AUTOSAR XML (schema 4-2-2)
package /ComponentTypes
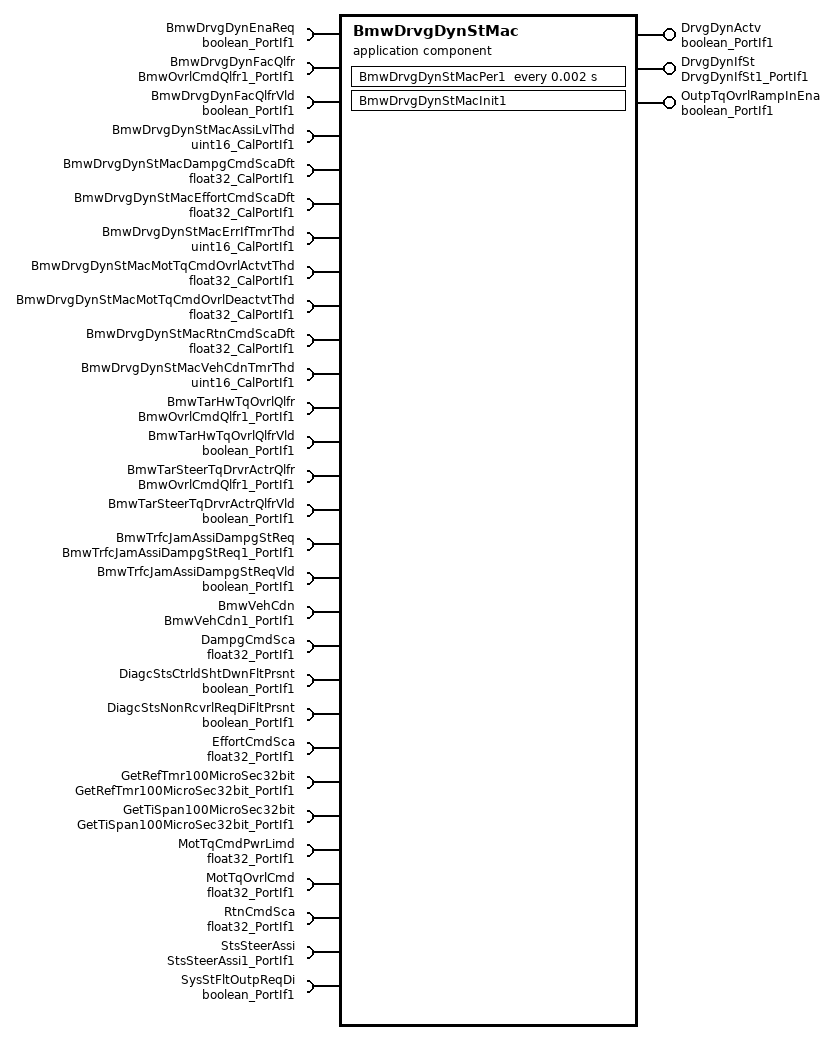
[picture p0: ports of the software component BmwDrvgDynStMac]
  application sw component type BmwDrvgDynStMac
    provide port DrvgDynActv: nonqueued-sender-com-spec{data-element=Logl, init-value=0}, provided-interface=boolean_PortIf1
    provide port DrvgDynIfSt: nonqueued-sender-com-spec{data-element=Val, init-value=128}, provided-interface=DrvgDynIfSt1_PortIf1
    provide port OutpTqOvrlRampInEna: nonqueued-sender-com-spec{data-element=Logl, init-value=0}, provided-interface=boolean_PortIf1
    29 x require port:
      BmwDrvgDynEnaReq: nonqueued-receiver-com-spec{data-element=Logl, filter=data-filter-type=ALWAYS, init-value=0}, required-interface=boolean_PortIf1
      BmwDrvgDynFacQlfr: nonqueued-receiver-com-spec{data-element=Val, filter=data-filter-type=ALWAYS, init-value=15}, required-interface=BmwOvrlCmdQlfr1_PortIf1
      BmwDrvgDynFacQlfrVld: nonqueued-receiver-com-spec{data-element=Logl, filter=data-filter-type=ALWAYS, init-value=0}, required-interface=boolean_PortIf1
      BmwDrvgDynStMacAssiLvlThd: parameter-require-com-spec{init-value=20, parameter=Val}, required-interface=uint16_CalPortIf1
      BmwDrvgDynStMacDampgCmdScaDft: parameter-require-com-spec{init-value=1, parameter=Val}, required-interface=float32_CalPortIf1
      BmwDrvgDynStMacEffortCmdScaDft: parameter-require-com-spec{init-value=1, parameter=Val}, required-interface=float32_CalPortIf1
      BmwDrvgDynStMacErrIfTmrThd: parameter-require-com-spec{init-value=20, parameter=Val}, required-interface=uint16_CalPortIf1
      BmwDrvgDynStMacMotTqCmdOvrlActvtThd: parameter-require-com-spec{init-value=0, parameter=Val}, required-interface=float32_CalPortIf1
      BmwDrvgDynStMacMotTqCmdOvrlDeactvtThd: parameter-require-com-spec{init-value=0, parameter=Val}, required-interface=float32_CalPortIf1
      BmwDrvgDynStMacRtnCmdScaDft: parameter-require-com-spec{init-value=1, parameter=Val}, required-interface=float32_CalPortIf1
      BmwDrvgDynStMacVehCdnTmrThd: parameter-require-com-spec{init-value=20, parameter=Val}, required-interface=uint16_CalPortIf1
      BmwTarHwTqOvrlQlfr: nonqueued-receiver-com-spec{data-element=Val, filter=data-filter-type=ALWAYS, init-value=15}, required-interface=BmwOvrlCmdQlfr1_PortIf1
      BmwTarHwTqOvrlQlfrVld: nonqueued-receiver-com-spec{data-element=Logl, filter=data-filter-type=ALWAYS, init-value=0}, required-interface=boolean_PortIf1
      BmwTarSteerTqDrvrActrQlfr: nonqueued-receiver-com-spec{data-element=Val, filter=data-filter-type=ALWAYS, init-value=15}, required-interface=BmwOvrlCmdQlfr1_PortIf1
      BmwTarSteerTqDrvrActrQlfrVld: nonqueued-receiver-com-spec{data-element=Logl, filter=data-filter-type=ALWAYS, init-value=0}, required-interface=boolean_PortIf1
      BmwTrfcJamAssiDampgStReq: nonqueued-receiver-com-spec{data-element=Val, filter=data-filter-type=ALWAYS, init-value=1}, required-interface=BmwTrfcJamAssiDampgStReq1_PortIf1
      BmwTrfcJamAssiDampgStReqVld: nonqueued-receiver-com-spec{data-element=Logl, filter=data-filter-type=ALWAYS, init-value=0}, required-interface=boolean_PortIf1
      BmwVehCdn: nonqueued-receiver-com-spec{data-element=Val, filter=data-filter-type=ALWAYS, init-value=15}, required-interface=BmwVehCdn1_PortIf1
      DampgCmdSca: nonqueued-receiver-com-spec{data-element=Val, filter=data-filter-type=ALWAYS, init-value=1}, required-interface=float32_PortIf1
      DiagcStsCtrldShtDwnFltPrsnt: nonqueued-receiver-com-spec{data-element=Logl, filter=data-filter-type=ALWAYS, init-value=0}, required-interface=boolean_PortIf1
      DiagcStsNonRcvrlReqDiFltPrsnt: nonqueued-receiver-com-spec{data-element=Logl, filter=data-filter-type=ALWAYS, init-value=0}, required-interface=boolean_PortIf1
      EffortCmdSca: nonqueued-receiver-com-spec{data-element=Val, filter=data-filter-type=ALWAYS, init-value=1}, required-interface=float32_PortIf1
      GetRefTmr100MicroSec32bit: client-com-spec=Oper, required-interface=GetRefTmr100MicroSec32bit_PortIf1
      GetTiSpan100MicroSec32bit: client-com-spec=Oper, required-interface=GetTiSpan100MicroSec32bit_PortIf1
      MotTqCmdPwrLimd: nonqueued-receiver-com-spec{data-element=Val, filter=data-filter-type=ALWAYS, init-value=0}, required-interface=float32_PortIf1
      MotTqOvrlCmd: nonqueued-receiver-com-spec{data-element=Val, filter=data-filter-type=ALWAYS, init-value=0}, required-interface=float32_PortIf1
      RtnCmdSca: nonqueued-receiver-com-spec{data-element=Val, filter=data-filter-type=ALWAYS, init-value=1}, required-interface=float32_PortIf1
      StsSteerAssi: nonqueued-receiver-com-spec{data-element=Val, filter=data-filter-type=ALWAYS, init-value=0}, required-interface=StsSteerAssi1_PortIf1
      SysStFltOutpReqDi: nonqueued-receiver-com-spec{data-element=Logl, filter=data-filter-type=ALWAYS, init-value=0}, required-interface=boolean_PortIf1
    behavior BmwDrvgDynStMac_InternalBehavior
      ar-typed-per-instance-memorys:
        7 x data, all with sw-calibration-access=READ-ONLY:
          AssiLvlActvtTi: type=uint32
          AssiLvlDeactvtTi: type=uint32
          ErrIfTi: type=uint32
          MotTqCmdPwrLimdCdnActvt: type=boolean
          MotTqCmdPwrLimdCdnDeactvt: type=boolean
          StMacSt: type=uint8
          VehCdnTi: type=uint32
      init event BmwDrvgDynStMac_InitEvent: start-on-event=BmwDrvgDynStMacInit1
      timing event TMT_BmwDrvgDynStMacPer1: start-on-event=BmwDrvgDynStMacPer1, period=0.002
      port-api-options:
        enable-take-address=false, error-handling=NO-TRANSFORMER-ERROR-HANDLING, indirect-api=false, port=BmwDrvgDynEnaReq
        enable-take-address=false, error-handling=NO-TRANSFORMER-ERROR-HANDLING, indirect-api=false, port=BmwDrvgDynFacQlfr
        enable-take-address=false, error-handling=NO-TRANSFORMER-ERROR-HANDLING, indirect-api=false, port=BmwDrvgDynFacQlfrVld
        enable-take-address=false, error-handling=NO-TRANSFORMER-ERROR-HANDLING, indirect-api=false, port=BmwDrvgDynStMacAssiLvlThd
        enable-take-address=false, error-handling=NO-TRANSFORMER-ERROR-HANDLING, indirect-api=false, port=BmwDrvgDynStMacDampgCmdScaDft
        enable-take-address=false, error-handling=NO-TRANSFORMER-ERROR-HANDLING, indirect-api=false, port=BmwDrvgDynStMacEffortCmdScaDft
        enable-take-address=false, error-handling=NO-TRANSFORMER-ERROR-HANDLING, indirect-api=false, port=BmwDrvgDynStMacErrIfTmrThd
        enable-take-address=false, error-handling=NO-TRANSFORMER-ERROR-HANDLING, indirect-api=false, port=BmwDrvgDynStMacMotTqCmdOvrlActvtThd
        enable-take-address=false, error-handling=NO-TRANSFORMER-ERROR-HANDLING, indirect-api=false, port=BmwDrvgDynStMacMotTqCmdOvrlDeactvtThd
        enable-take-address=false, error-handling=NO-TRANSFORMER-ERROR-HANDLING, indirect-api=false, port=BmwDrvgDynStMacRtnCmdScaDft
        enable-take-address=false, error-handling=NO-TRANSFORMER-ERROR-HANDLING, indirect-api=false, port=BmwDrvgDynStMacVehCdnTmrThd
        enable-take-address=false, error-handling=NO-TRANSFORMER-ERROR-HANDLING, indirect-api=false, port=BmwTarHwTqOvrlQlfr
        enable-take-address=false, error-handling=NO-TRANSFORMER-ERROR-HANDLING, indirect-api=false, port=BmwTarHwTqOvrlQlfrVld
        enable-take-address=false, error-handling=NO-TRANSFORMER-ERROR-HANDLING, indirect-api=false, port=BmwTarSteerTqDrvrActrQlfr
        enable-take-address=false, error-handling=NO-TRANSFORMER-ERROR-HANDLING, indirect-api=false, port=BmwTarSteerTqDrvrActrQlfrVld
        enable-take-address=false, error-handling=NO-TRANSFORMER-ERROR-HANDLING, indirect-api=false, port=BmwTrfcJamAssiDampgStReq
        enable-take-address=false, error-handling=NO-TRANSFORMER-ERROR-HANDLING, indirect-api=false, port=BmwTrfcJamAssiDampgStReqVld
        enable-take-address=false, error-handling=NO-TRANSFORMER-ERROR-HANDLING, indirect-api=false, port=BmwVehCdn
        enable-take-address=false, error-handling=NO-TRANSFORMER-ERROR-HANDLING, indirect-api=false, port=DampgCmdSca
        enable-take-address=false, error-handling=NO-TRANSFORMER-ERROR-HANDLING, indirect-api=false, port=DiagcStsCtrldShtDwnFltPrsnt
        enable-take-address=false, error-handling=NO-TRANSFORMER-ERROR-HANDLING, indirect-api=false, port=DiagcStsNonRcvrlReqDiFltPrsnt
        enable-take-address=false, error-handling=NO-TRANSFORMER-ERROR-HANDLING, indirect-api=false, port=DrvgDynActv
        enable-take-address=false, error-handling=NO-TRANSFORMER-ERROR-HANDLING, indirect-api=false, port=DrvgDynIfSt
        enable-take-address=false, error-handling=NO-TRANSFORMER-ERROR-HANDLING, indirect-api=false, port=EffortCmdSca
        enable-take-address=false, error-handling=NO-TRANSFORMER-ERROR-HANDLING, indirect-api=false, port=GetRefTmr100MicroSec32bit
        enable-take-address=false, error-handling=NO-TRANSFORMER-ERROR-HANDLING, indirect-api=false, port=GetTiSpan100MicroSec32bit
        enable-take-address=false, error-handling=NO-TRANSFORMER-ERROR-HANDLING, indirect-api=false, port=MotTqCmdPwrLimd
        enable-take-address=false, error-handling=NO-TRANSFORMER-ERROR-HANDLING, indirect-api=false, port=MotTqOvrlCmd
        enable-take-address=false, error-handling=NO-TRANSFORMER-ERROR-HANDLING, indirect-api=false, port=OutpTqOvrlRampInEna
        enable-take-address=false, error-handling=NO-TRANSFORMER-ERROR-HANDLING, indirect-api=false, port=RtnCmdSca
        enable-take-address=false, error-handling=NO-TRANSFORMER-ERROR-HANDLING, indirect-api=false, port=StsSteerAssi
        enable-take-address=false, error-handling=NO-TRANSFORMER-ERROR-HANDLING, indirect-api=false, port=SysStFltOutpReqDi
      runnable BmwDrvgDynStMacInit1
        data-receive-point-by-arguments:
          access REC_MotTqCmdPwrLimd_Val: accessed-variable=MotTqCmdPwrLimd.Val
      runnable BmwDrvgDynStMacPer1
        data-receive-point-by-arguments:
          19 x access:
            REC_BmwDrvgDynEnaReq_Logl: accessed-variable=BmwDrvgDynEnaReq.Logl
            REC_BmwDrvgDynFacQlfr_Val: accessed-variable=BmwDrvgDynFacQlfr.Val
            REC_BmwDrvgDynFacQlfrVld_Logl: accessed-variable=BmwDrvgDynFacQlfrVld.Logl
            REC_BmwTarHwTqOvrlQlfr_Val: accessed-variable=BmwTarHwTqOvrlQlfr.Val
            REC_BmwTarHwTqOvrlQlfrVld_Logl: accessed-variable=BmwTarHwTqOvrlQlfrVld.Logl
            REC_BmwTarSteerTqDrvrActrQlfr_Val: accessed-variable=BmwTarSteerTqDrvrActrQlfr.Val
            REC_BmwTarSteerTqDrvrActrQlfrVld_Logl: accessed-variable=BmwTarSteerTqDrvrActrQlfrVld.Logl
            REC_BmwTrfcJamAssiDampgStReq_Val: accessed-variable=BmwTrfcJamAssiDampgStReq.Val
            REC_BmwTrfcJamAssiDampgStReqVld_Logl: accessed-variable=BmwTrfcJamAssiDampgStReqVld.Logl
            REC_BmwVehCdn_Val: accessed-variable=BmwVehCdn.Val
            REC_DampgCmdSca_Val: accessed-variable=DampgCmdSca.Val
            REC_DiagcStsCtrldShtDwnFltPrsnt_Logl: accessed-variable=DiagcStsCtrldShtDwnFltPrsnt.Logl
            REC_DiagcStsNonRcvrlReqDiFltPrsnt_Logl: accessed-variable=DiagcStsNonRcvrlReqDiFltPrsnt.Logl
            REC_EffortCmdSca_Val: accessed-variable=EffortCmdSca.Val
            REC_MotTqCmdPwrLimd_Val: accessed-variable=MotTqCmdPwrLimd.Val
            REC_MotTqOvrlCmd_Val: accessed-variable=MotTqOvrlCmd.Val
            REC_RtnCmdSca_Val: accessed-variable=RtnCmdSca.Val
            REC_StsSteerAssi_Val: accessed-variable=StsSteerAssi.Val
            REC_SysStFltOutpReqDi_Logl: accessed-variable=SysStFltOutpReqDi.Logl
        data-send-points:
          access SEND_DrvgDynActv_Logl: accessed-variable=DrvgDynActv.Logl
          access SEND_DrvgDynIfSt_Val: accessed-variable=DrvgDynIfSt.Val
          access SEND_OutpTqOvrlRampInEna_Logl: accessed-variable=OutpTqOvrlRampInEna.Logl
        sync call SC_GetRefTmr100MicroSec32bit_Oper: operation=GetRefTmr100MicroSec32bit.Oper, timeout=0
        sync call SC_GetTiSpan100MicroSec32bit_Oper: operation=GetTiSpan100MicroSec32bit.Oper, timeout=0
  swc implementation BmwDrvgDynStMac_Implementation: behavior=BmwDrvgDynStMac_InternalBehavior
    code-descriptors:
      code Default: artifact-descriptors=autosar-engineering-object={short-label=Default, category=SWSRC}
